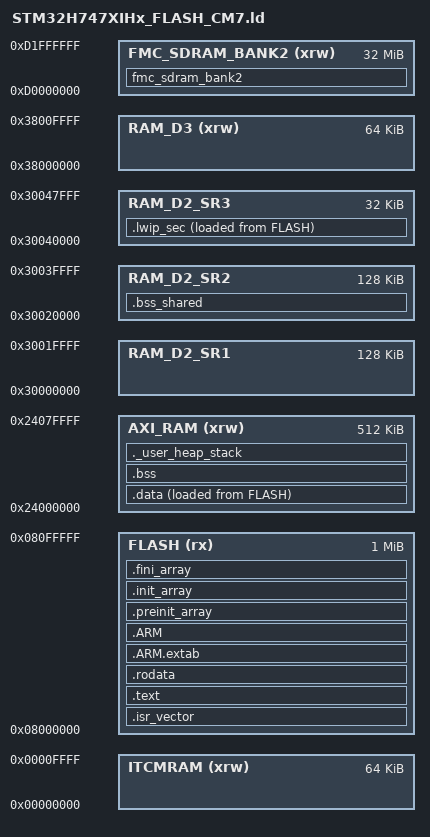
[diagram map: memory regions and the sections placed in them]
/*
******************************************************************************
**

**  File        : LinkerScript.ld
**
**
**
**  Abstract    : Linker script for STM32H7 series
**                1024Kbytes FLASH and 192Kbytes RAM
**
**                Set heap size, stack size and stack location according
**                to application requirements.
**
**                Set memory bank area and size if external memory is used.
**
**  Target      : STMicroelectronics STM32
**
**  Distribution: The file is distributed as is, without any warranty
**                of any kind.
**
*****************************************************************************
** @attention
**
** Copyright (c) 2019 STMicroelectronics.
** All rights reserved.
**
** This software is licensed under terms that can be found in the LICENSE file
** in the root directory of this software component.
** If no LICENSE file comes with this software, it is provided AS-IS.
**
******************************************************************************
*/

/* clang-format off*/

/* Entry Point */
ENTRY(Reset_Handler)

/* Highest address of the user mode stack */
_estack = 0x24080000;    /* end of RAM */
/* Generate a link error if heap and stack don't fit into RAM */
_Min_Heap_Size = 0x200;      /* required amount of heap  */
_Min_Stack_Size = 0x400; /* required amount of stack */

/* Specify the memory areas */
MEMORY
{
FLASH (rx)           : ORIGIN = 0x08000000, LENGTH = 1024K
AXI_RAM (xrw)        : ORIGIN = 0x24000000, LENGTH = 512K
RAM_D2_SR1           : ORIGIN = 0x30000000, LENGTH = 128K
RAM_D2_SR2           : ORIGIN = 0x30020000, LENGTH = 128K
RAM_D2_SR3           : ORIGIN = 0x30040000, LENGTH = 32K
RAM_D3 (xrw)         : ORIGIN = 0x38000000, LENGTH = 64K
ITCMRAM (xrw)        : ORIGIN = 0x00000000, LENGTH = 64K
FMC_SDRAM_BANK2(xrw) : ORIGIN = 0xD0000000, LENGTH = 32M
}

/* Define output sections */
SECTIONS
{
  /* The startup code goes first into FLASH */
  .isr_vector :
  {
    . = ALIGN(4);
    KEEP(*(.isr_vector)) /* Startup code */
    . = ALIGN(4);
  } >FLASH

  /* The program code and other data goes into FLASH */
  .text :
  {
    . = ALIGN(4);
    *(.text)           /* .text sections (code) */
    *(.text*)          /* .text* sections (code) */
    *(.glue_7)         /* glue arm to thumb code */
    *(.glue_7t)        /* glue thumb to arm code */
    *(.eh_frame)

    KEEP (*(.init))
    KEEP (*(.fini))

    . = ALIGN(4);
    _etext = .;        /* define a global symbols at end of code */
  } >FLASH

  /* Constant data goes into FLASH */
  .rodata :
  {
    . = ALIGN(4);
    *(.rodata)         /* .rodata sections (constants, strings, etc.) */
    *(.rodata*)        /* .rodata* sections (constants, strings, etc.) */
    . = ALIGN(4);
  } >FLASH

  .ARM.extab   : { *(.ARM.extab* .gnu.linkonce.armextab.*) } >FLASH
  .ARM : {
    __exidx_start = .;
    *(.ARM.exidx*)
    __exidx_end = .;
  } >FLASH

  .preinit_array     :
  {
    PROVIDE_HIDDEN (__preinit_array_start = .);
    KEEP (*(.preinit_array*))
    PROVIDE_HIDDEN (__preinit_array_end = .);
  } >FLASH
  .init_array :
  {
    PROVIDE_HIDDEN (__init_array_start = .);
    KEEP (*(SORT(.init_array.*)))
    KEEP (*(.init_array*))
    PROVIDE_HIDDEN (__init_array_end = .);
  } >FLASH
  .fini_array :
  {
    PROVIDE_HIDDEN (__fini_array_start = .);
    KEEP (*(SORT(.fini_array.*)))
    KEEP (*(.fini_array*))
    PROVIDE_HIDDEN (__fini_array_end = .);
  } >FLASH

  /* used by the startup to initialize data */
  _sidata = LOADADDR(.data);

  /* Initialized data sections goes into RAM, load LMA copy after code */
  .data : 
  {
    . = ALIGN(4);
    _sdata = .;        /* create a global symbol at data start */
    *(.data)           /* .data sections */
    *(.data*)          /* .data* sections */

    . = ALIGN(4);
    _edata = .;        /* define a global symbol at data end */
  } >AXI_RAM AT> FLASH

  
  /* Uninitialized data section */
  . = ALIGN(4);
  .bss :
  {
    /* This is used by the startup in order to initialize the .bss section */
    _sbss = .;         /* define a global symbol at bss start */
    __bss_start__ = _sbss;
    *(.bss)
    *(.bss*)
    *(COMMON)

    . = ALIGN(4);
    _ebss = .;         /* define a global symbol at bss end */
    __bss_end__ = _ebss;
  } >AXI_RAM

  /* User_heap_stack section, used to check that there is enough RAM left */
  ._user_heap_stack :
  {
    . = ALIGN(8);
    PROVIDE ( end = . );
    PROVIDE ( _end = . );
    . = . + _Min_Heap_Size;
    . = . + _Min_Stack_Size;
    . = ALIGN(8);
  } >AXI_RAM

  fmc_sdram_bank2(NOLOAD) :
  {
    . = ALIGN(4);
    KEEP(*(.sdram_bank2))
    . = ALIGN(4);
  } >FMC_SDRAM_BANK2

  /* Remove information from the standard libraries */
  /DISCARD/ :
  {
    libc.a ( * )
    libm.a ( * )
    libgcc.a ( * )
  }

  .bss_shared(NOLOAD) : {
  	. = ABSOLUTE(0x30020000);
    _sbss_shared = .;         /* define a global symbol at bss_share start */
  	. = ALIGN(4);
  	KEEP(*(.uart_struct));
  	. = ALIGN(4);
  	KEEP(*(.diag_buffer));
  	. = ALIGN(4);
  	KEEP(*(.diag_fifo));
  	. = ALIGN(4);
  	_ebss_shared = .;         /* define a global symbol at bss_share end */
  } >RAM_D2_SR2 
 
  .lwip_sec (NOLOAD) : {
    . = ABSOLUTE(0x30040000);
    *(.RxDecripSection) 
    
    . = ABSOLUTE(0x30040060);
    *(.TxDecripSection)
    
    . = ABSOLUTE(0x30040200);
    *(.RxArraySection) 
  } >RAM_D2_SR3 AT> FLASH
  
  .ARM.attributes 0 : { *(.ARM.attributes) }
}


